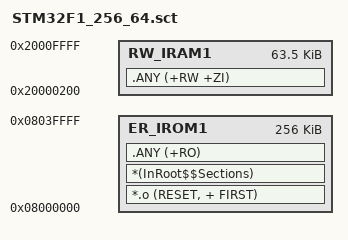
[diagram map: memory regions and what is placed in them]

LR_IROM1 0x08000000 0x00040000  {    ; load region size_region
  ER_IROM1 0x08000000 0x00040000  {  ; load address = execution address
   *.o (RESET, + FIRST)
   *(InRoot$$Sections)
   .ANY (+RO)
  }
  RW_IRAM1 0x20000200 0x0000fe00  {  ; RW data
   .ANY (+RW +ZI)
  }
}

